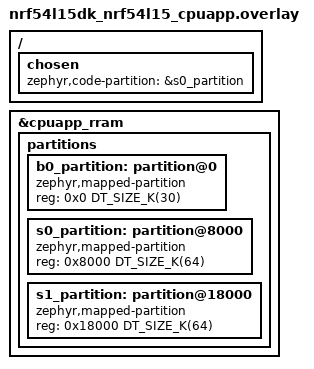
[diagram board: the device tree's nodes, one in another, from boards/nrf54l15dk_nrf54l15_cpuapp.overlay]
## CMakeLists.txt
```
#
# Copyright (c) 2025 Nordic Semiconductor
#
# SPDX-License-Identifier: LicenseRef-Nordic-5-Clause
#

cmake_minimum_required(VERSION 3.20.0)

find_package(Zephyr REQUIRED HINTS $ENV{ZEPHYR_BASE})
project(b0_ram_cleanup)

FILE(GLOB app_sources src/*.c)
target_sources(app PRIVATE ${app_sources})
target_include_directories(app PRIVATE .)
```

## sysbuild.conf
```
#
# Copyright (c) 2025-2026 Nordic Semiconductor
#
# SPDX-License-Identifier: LicenseRef-Nordic-5-Clause
#

SB_CONFIG_SECURE_BOOT_APPCORE=y
SB_CONFIG_SECURE_BOOT_GENERATE_DEFAULT_KMU_KEYFILE=y
```

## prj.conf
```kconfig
#
# Copyright (c) 2025 Nordic Semiconductor ASA
#
# SPDX-License-Identifier: LicenseRef-Nordic-5-Clause
#
CONFIG_ZTEST=y
CONFIG_ARM_MPU=n
CONFIG_SOC_EARLY_RESET_HOOK=y
```

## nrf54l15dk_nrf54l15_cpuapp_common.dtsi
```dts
/*
 * Copyright (c) 2025 Nordic Semiconductor ASA
 *
 * SPDX-License-Identifier: LicenseRef-Nordic-5-Clause
 */

/ {
	cpuapp_sram@2003fff0 {
		compatible = "zephyr,memory-region", "mmio-sram";
		reg = <0x2003fff0 0x10>;
		zephyr,memory-region = "RetainedMem";
		status = "okay";

		retainedmem {
			compatible = "zephyr,retained-ram";
			status = "okay";
			#address-cells = <1>;
			#size-cells = <1>;

			test_retention_area: test_retention_area@0 {
				compatible = "zephyr,retention";
				status = "okay";
				reg = <0x0 0x10>;
				prefix = [0b 01];
				checksum = <4>;
			};
		};
	};
};
```

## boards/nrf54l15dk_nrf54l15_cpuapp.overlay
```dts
/*
 * Copyright (c) 2026 Nordic Semiconductor ASA
 *
 * SPDX-License-Identifier: LicenseRef-Nordic-5-Clause
 */

&cpuapp_rram {
	/delete-node/ partitions;

	partitions {
		ranges;
		#address-cells = <1>;
		#size-cells = <1>;

		b0_partition: partition@0 {
			compatible = "zephyr,mapped-partition";
			reg = <0x0 DT_SIZE_K(30)>;
		};

		s0_partition: partition@8000 {
			compatible = "zephyr,mapped-partition";
			reg = <0x8000 DT_SIZE_K(64)>;
		};

		s1_partition: partition@18000 {
			compatible = "zephyr,mapped-partition";
			reg = <0x18000 DT_SIZE_K(64)>;
		};
	};
};

/ {
	chosen {
		zephyr,code-partition = &s0_partition;
	};
};
```

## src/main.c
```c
/*
 * Copyright (c) 2025 Nordic Semiconductor ASA
 *
 * SPDX-License-Identifier: LicenseRef-Nordic-5-Clause
 */

#include <zephyr/ztest.h>
#include <hal/nrf_timer.h>

/* As peripheral registers are not cleared during RAM cleanup, we can
 * use a register of a peripheral unused by NSIB to save data which can then
 * be read by the application.
 * We use this trick to save the start and end addresses of the RAMFUNC region.
 * This region is not cleared during the RAM cleanup, as it contains the code responsible
 * for performing the RAM cleanup, so it must be skipped when checking if the RAM cleanup
 * has been successfully performed.
 * The TIMER00 is not used by NSIB, and is therefore its CC[0] and CC[1] registers
 * are used for this purpose.
 */
#define RAMFUNC_START_SAVE_REGISTER NRF_TIMER00->CC[0]
#define RAMFUNC_END_SAVE_REGISTER NRF_TIMER00->CC[1]

/* Using 2-byte magic values allows to load the whole value with movw */
#define RAM_CLEANUP_SUCCESS_MAGIC 0x5678
#define RAM_CLEANUP_FAILURE_MAGIC 0x4321

static uint32_t __noinit ram_cleanup_result;
static uint32_t __noinit uncleared_address;
static uint32_t __noinit uncleared_value;

/**
 * This hook needs to have the attribute __attribute__((naked)),
 * as otherwise the stack would be modified when calling it, leading to
 * test failure, as part of the RAM in which the stack resides wouldn't
 * be zeroed.
 */
__attribute__((naked)) void soc_early_reset_hook(void)
{
	__asm__ volatile (
		/* Load zero (value used to clear memory) into r0 */
		"   mov  r0, #0\n"
		/*  Explicitly clear the ram_cleanup_result variable */
		"   mov  r2, %6\n"
		"   str  r0, [r2]\n"
		/* Load the location of the saved ram func start address to r1 */
		"   mov  r1, %0\n"
		/* Load the ram func start address to r2 */
		"   ldr  r2, [r1]\n"
		/* Load the location of the saved ram func end address to r1 */
		"   mov  r1, %1\n"
		/* Load the ram func end address to r3*/
		"   ldr  r3, [r1]\n"
		/* Clear memory from ram func start to ram func end.
		 * The area is skipped during the RAM cleanup,
		 * so it is not cleared.
		 * Simply cleaning it up here is quicker
		 * than verifying if the current address is within the gap
		 * in each iteration of the loop.
		 */
		"ram_func_zero_loop:\n"
		"   cmp  r2, r3\n"
		"   bge  ram_func_zero_loop_done\n"
		"   str  r0, [r2]\n"
		/* Increment the address by 4 (word size) */
		"   add  r2, r2, #4\n"
		"   b    ram_func_zero_loop\n"
		"ram_func_zero_loop_done:\n"
		/* Verify that all of the RAM memory has been cleared */
		/* Load SRAM base address to r1 */
		"   mov  r1, %2\n"
		/* Load SRAM size to r2 */
		"   mov  r2, %3\n"
		/* Calculate SRAM end address (base + size) */
		"   add  r2, r1, r2\n"
		"verify_ram_loop:\n"
		"   cmp  r1, r2\n"
		"   bge  verify_ram_done\n"
		/* Load value at current address and verify if it equals 0 */
		"   ldr  r3, [r1]\n"
		"   cmp  r3, #0\n"
		"   bne  ram_cleanup_failed\n"
		/* Increment the address by 4 (word size) */
		"   add  r1, r1, #4\n"
		"   b    verify_ram_loop\n"
		"ram_cleanup_failed:\n"
		/* Load RAM_CLEANUP_FAILURE_MAGIC into r0 */
		"   movw r0, %4\n"
		/* Save the uncleared address in uncleared_address variable */
		"   mov  r2, %7\n"
		"   str  r1, [r2]\n"
		/* Save the uncleared value in uncleared_value variable */
		"   mov  r2, %8\n"
		"   str  r3, [r2]\n"
		"   b    verification_done\n"
		"verify_ram_done:\n"
		/* Load RAM_CLEANUP_SUCCESS_MAGIC */
		"   movw r0, %5\n"
		"verification_done:\n"
		/* Store result in ram_cleanup_result variable */
		"   mov  r2, %6\n"
		"   str  r0, [r2]\n"
		/* __attribute__((naked)) requires manual branching  */
		"   bx   lr\n"
		:
		: "r" (&RAMFUNC_START_SAVE_REGISTER),
		  "r" (&RAMFUNC_END_SAVE_REGISTER),
		  "r" (CONFIG_SRAM_BASE_ADDRESS),
		  "r" (CONFIG_SRAM_SIZE * 1024),
		  "i" (RAM_CLEANUP_FAILURE_MAGIC),
		  "i" (RAM_CLEANUP_SUCCESS_MAGIC),
		  "r" (&ram_cleanup_result),
		  "r" (&uncleared_address),
		  "r" (&uncleared_value)
		: "r0", "r1", "r2", "r3", "lr", "memory"
	);
}

ZTEST(b0_ram_cleanup, test_ram_cleanup)
{
	zassert_true((ram_cleanup_result == RAM_CLEANUP_SUCCESS_MAGIC) ||
		     (ram_cleanup_result == RAM_CLEANUP_FAILURE_MAGIC),
		     "RAM cleanup result should be either success or failure");
	zassert_equal(ram_cleanup_result, RAM_CLEANUP_SUCCESS_MAGIC,
		      "Uncleared word detected at address %p, value 0x%x",
		      (void *) uncleared_address, uncleared_value);
}

ZTEST_SUITE(b0_ram_cleanup, NULL, NULL, NULL, NULL, NULL);
```
